# GD32A513 register map
File version: 1.0
CPU: CM33 r0p4, little endian, MPU, FPU, 4 interrupt priority bits
Registers are 32-bit, read-write, reset 0x0 unless marked. A register's access mark holds for its fields unless they carry their own. Offsets are from the block's base; [hi:lo] are bit positions; {n}, {i} and the like mark numbered series.

## NVIC — Nested Vectored Interrupt Controller
Base 0xE000E100
{0x0+4i} ISER{i} (i=0..15) — Interrupt Set Enable Register
  [31:0] SETENA
0x80 ICER0 — Interrupt Clear Enable Register
  [31:0] CLRENA
0x84 ICER1 — Interrupt Clear Enable Register
  [31:0] CLRENA
{0x84+4i} ICER{i} (i=2..15) — Interrupt Clear Enable Register
  [31:0] CLRENA
{0x100+4i} ISPR{i} (i=0..15) — Interrupt Set-Pending Register
  [31:0] SETPEND
{0x180+4i} ICPR{i} (i=0..15) — Interrupt Clear-Pending Register
  [31:0] CLRPEND
{0x200+4i} IABR{i} (i=0..15) — Interrupt Active bit Register
  [31:0] IABR
{0x280+4i} ITNS{i} (i=0..15) — Interrupt Active bit Register
  [31:0] ITNS
{0x300+i} IPR{i} 8-bit (i=0..31) — Interrupt Priority Register {i}
  [7:0] PRI_{i:02}

## PMU — Power management unit
Base 0x40007000
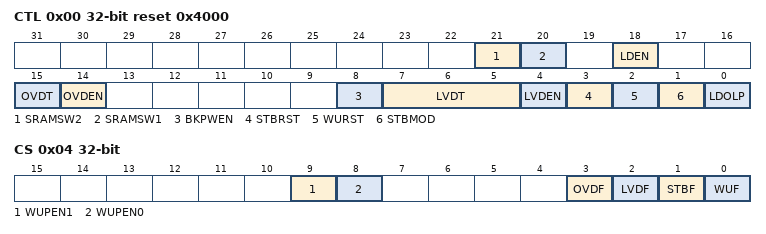
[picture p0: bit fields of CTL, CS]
0x00 CTL reset 0x4000 — power control register
  [21] SRAMSW2 — SRAM2(32KB~48KB) power switch in deep-sleep mode
  [20] SRAMSW1 — SRAM1(16KB~32KB) power switch in deep-sleep mode
  [18] LDEN — Low-driver mode enable in Deep-sleep mode
  [15] OVDT — Over Voltage Detector Threshold
  [14] OVDEN — Over Voltage Detector Enable
  [8] BKPWEN — Backup Domain Write Enable
  [7:5] LVDT — Low Voltage Detector Threshold
  [4] LVDEN — Low Voltage Detector Enable
  [3] STBRST — Standby Flag Reset
  [2] WURST — Wakeup Flag Reset
  [1] STBMOD — Standby Mode
  [0] LDOLP — LDO Low Power Mode
0x04 CS access per field — power control/status register
  [9] WUPEN1 rw — WKUP pin1 Enable
  [8] WUPEN0 rw — WKUP pin0 Enable
  [3] OVDF ro — Low Voltage Detector Status Flag
  [2] LVDF ro — Low Voltage Detector Status Flag
  [1] STBF ro — Standby flag
  [0] WUF ro — Wakeup flag

## SYSCFG — System configuration controller
Base 0x40010000
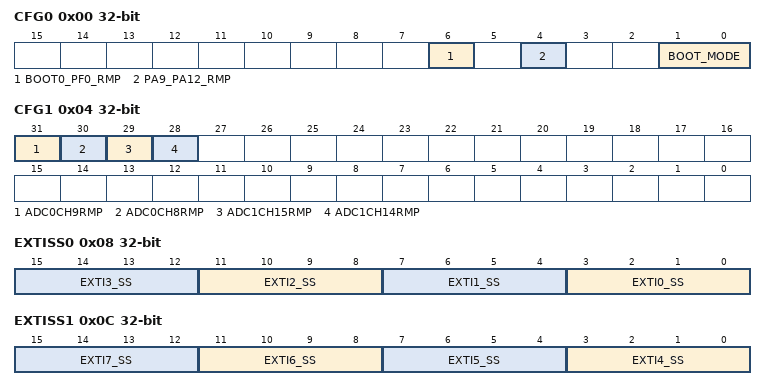
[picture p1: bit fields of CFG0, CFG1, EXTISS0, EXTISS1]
0x00 CFG0 — System configuration register 0
  [6] BOOT0_PF0_RMP — BOOT0 and PF0 remapping bit
  [4] PA9_PA12_RMP — PA9 and PA12 remapping bit for small packages
  [1:0] BOOT_MODE
0x04 CFG1 — System configuration register 1
  [31] ADC0CH9RMP — ADC0 channel 9 remapping bit
  [30] ADC0CH8RMP — ADC0 channel 8 remapping bit
  [29] ADC1CH15RMP — ADC1 channel 15 remapping bit
  [28] ADC1CH14RMP — ADC1 channel 14 remapping bit
0x08 EXTISS0 — EXTI sources selection register 0
  [4n+3:4n] EXTI{n}_SS (n=0..3) — EXTI {n} sources selection
0x0C EXTISS1 — EXTI sources selection register 1
  [4n-13:4n-16] EXTI{n}_SS (n=4..7) — EXTI {n} sources selection
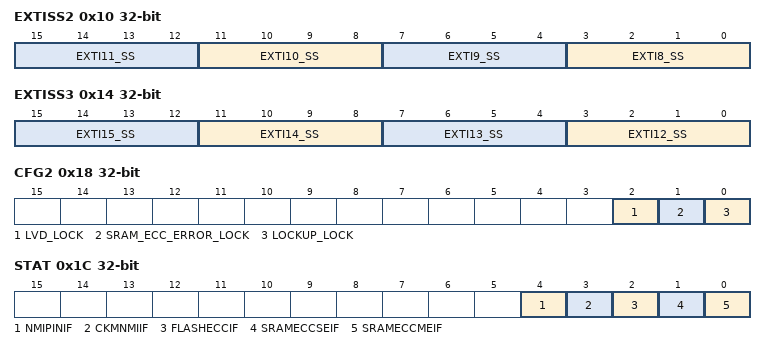
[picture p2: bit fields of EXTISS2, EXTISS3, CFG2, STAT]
0x10 EXTISS2 — EXTI sources selection register 2
  [4n-29:4n-32] EXTI{n}_SS (n=8..11) — EXTI {n} sources selection
0x14 EXTISS3 — EXTI sources selection register 3
  [4n-45:4n-48] EXTI{n}_SS (n=12..15) — EXTI {n} sources selection
0x18 CFG2 — System configuration register 2
  [2] LVD_LOCK
  [1] SRAM_ECC_ERROR_LOCK — SRAM ECC check error lock
  [0] LOCKUP_LOCK — Cortex-M33 LOCKUP output lock
0x1C STAT access per field — System status register
  [4] NMIPINIF ro — Interrupt flag from NMI pin
  [3] CKMNMIIF rw — HXTAL clock moniotor NMI interrupt flag
  [2] FLASHECCIF rw — Flash ECC interrupt flag
  [1] SRAMECCSEIF rw — SRAM single bit correction event flag
  [0] SRAMECCMEIF rw — SRAM multi-bits non-correction event flag
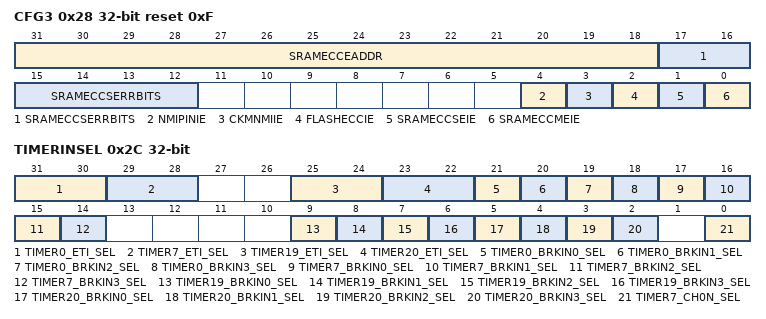
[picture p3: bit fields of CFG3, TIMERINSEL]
0x28 CFG3 access per field reset 0xF — System configuration register 3
  [31:18] SRAMECCEADDR ro — Record the faulting system address
  [17:12] SRAMECCSERRBITS ro — Which one bit has an SRAM ECC single-bit correctable error
  [4] NMIPINIE rw — NMI pin interrupt enable
  [3] CKMNMIIE rw — HXTAL clock moniotor NMI enable
  [2] FLASHECCIE rw — Flash ECC NMI enable
  [1] SRAMECCSEIE rw — SRAM single bit correction interrupt enable
  [0] SRAMECCMEIE rw — SRAM multi-bits non-correction interrupt enable
0x2C TIMERINSEL — TIMER input source select register
  [31:30] TIMER0_ETI_SEL — TIMER0 external trigger select
  [29:28] TIMER7_ETI_SEL — TIMER7 external trigger select
  [25:24] TIMER19_ETI_SEL — TIMER19 external trigger select
  [23:22] TIMER20_ETI_SEL — TIMER20 external trigger select
  [21-n] TIMER0_BRKIN{n}_SEL (n=0..3) — TIMER0 break input {n} select
  [17-n] TIMER7_BRKIN{n}_SEL (n=0..3) — TIMER7 break input {n} select
  [9-n] TIMER19_BRKIN{n}_SEL (n=0..3) — TIMER19 break input {n} select
  [5-n] TIMER20_BRKIN{n}_SEL (n=0..3) — TIMER20 break input {n} select
  [0] TIMER7_CH0N_SEL — TIMER7 Channel 0 complementary input select
